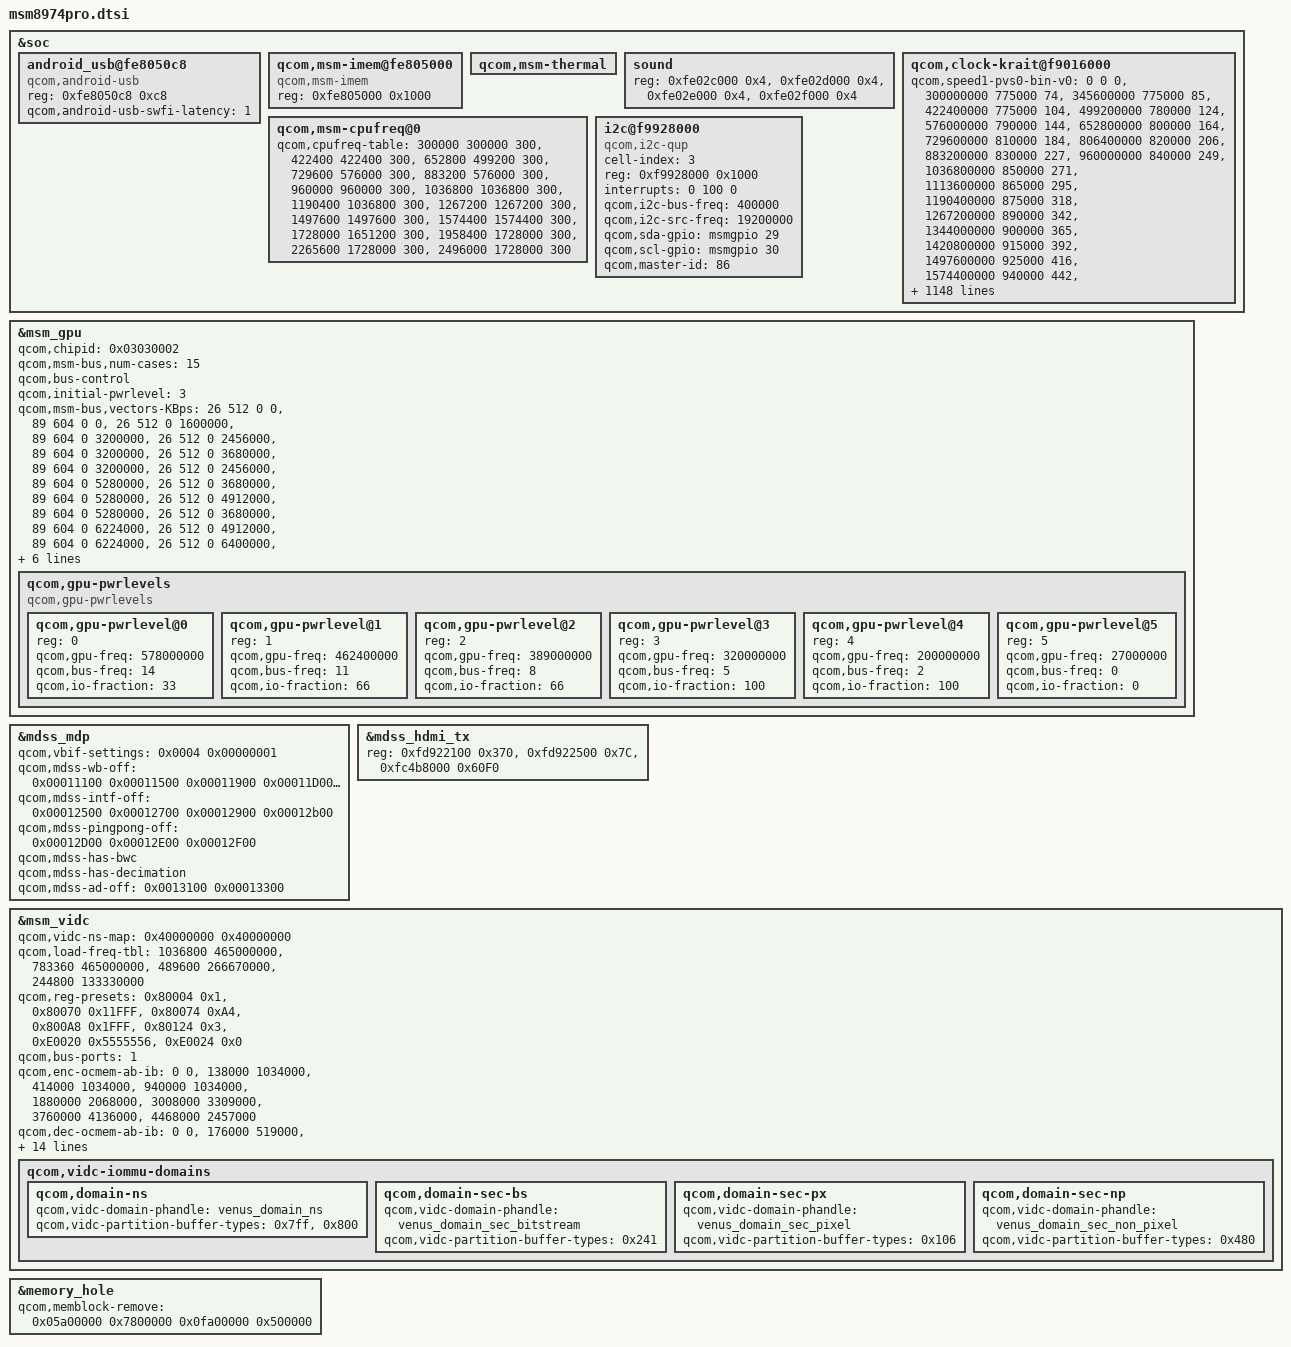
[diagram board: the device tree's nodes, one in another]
/* Copyright (c) 2013, The Linux Foundation. All rights reserved.
 *
 * This program is free software; you can redistribute it and/or modify
 * it under the terms of the GNU General Public License version 2 and
 * only version 2 as published by the Free Software Foundation.
 *
 * This program is distributed in the hope that it will be useful,
 * but WITHOUT ANY WARRANTY; without even the implied warranty of
 * MERCHANTABILITY or FITNESS FOR A PARTICULAR PURPOSE.  See the
 * GNU General Public License for more details.
 */

/*
 * As a general rule, only version-specific property overrides should be placed
 * inside this file. However, device definitions should be placed inside the
 * msm8974.dtsi file.
 */

/include/ "msm8974.dtsi"
/include/ "msm8974-v2-iommu.dtsi"
/include/ "msm8974-v2-iommu-domains.dtsi"
/include/ "msm8974pro-pm.dtsi"
/include/ "msm8974pro-ion.dtsi"

&soc {
	android_usb@fe8050c8 {
		compatible = "qcom,android-usb";
		reg = <0xfe8050c8 0xc8>;
		qcom,android-usb-swfi-latency = <1>;
	};

	qcom,msm-imem@fe805000 {
		compatible = "qcom,msm-imem";
		reg = <0xfe805000 0x1000>; /* Address and size of IMEM */
	};

	qcom,msm-thermal {
		/delete-property/ qcom,pmic-sw-mode-temp;
		/delete-property/ qcom,pmic-sw-mode-temp-hysteresis;
		/delete-property/ qcom,pmic-sw-mode-regs;
	};

	sound {
		reg = <0xfe02c000 0x4>,
		      <0xfe02d000 0x4>,
		      <0xfe02e000 0x4>,
		      <0xfe02f000 0x4>;
		reg-names = "lpaif_pri_mode_muxsel",
			    "lpaif_sec_mode_muxsel",
			    "lpaif_tert_mode_muxsel",
			    "lpaif_quat_mode_muxsel";
	};

	qcom,clock-krait@f9016000 {
		qcom,speed1-pvs0-bin-v0 =
			<          0       0    0 >,
			<  300000000  775000   74 >,
			<  345600000  775000   85 >,
			<  422400000  775000  104 >,
			<  499200000  780000  124 >,
			<  576000000  790000  144 >,
			<  652800000  800000  164 >,
			<  729600000  810000  184 >,
			<  806400000  820000  206 >,
			<  883200000  830000  227 >,
			<  960000000  840000  249 >,
			< 1036800000  850000  271 >,
			< 1113600000  865000  295 >,
			< 1190400000  875000  318 >,
			< 1267200000  890000  342 >,
			< 1344000000  900000  365 >,
			< 1420800000  915000  392 >,
			< 1497600000  925000  416 >,
			< 1574400000  940000  442 >,
			< 1651200000  955000  469 >,
			< 1728000000  970000  497 >,
			< 1804800000  985000  525 >,
			< 1881600000 1000000  554 >,
			< 1958400000 1015000  583 >,
			< 2035200000 1030000  613 >,
			< 2112000000 1045000  642 >,
			< 2150400000 1060000  663 >,
			< 2188800000 1060000  675 >,
			< 2265600000 1075000  708 >;

		qcom,speed1-pvs1-bin-v0 =
			<          0       0    0 >,
			<  300000000  775000   74 >,
			<  345600000  775000   85 >,
			<  422400000  775000  104 >,
			<  499200000  775000  124 >,
			<  576000000  775000  144 >,
			<  652800000  785000  164 >,
			<  729600000  795000  184 >,
			<  806400000  805000  206 >,
			<  883200000  815000  227 >,
			<  960000000  825000  249 >,
			< 1036800000  835000  271 >,
			< 1113600000  850000  295 >,
			< 1190400000  860000  318 >,
			< 1267200000  870000  342 >,
			< 1344000000  885000  365 >,
			< 1420800000  895000  392 >,
			< 1497600000  905000  416 >,
			< 1574400000  920000  442 >,
			< 1651200000  935000  469 >,
			< 1728000000  950000  497 >,
			< 1804800000  965000  525 >,
			< 1881600000  980000  554 >,
			< 1958400000  995000  583 >,
			< 2035200000 1005000  613 >,
			< 2112000000 1020000  642 >,
			< 2150400000 1035000  663 >,
			< 2188800000 1035000  675 >,
			< 2265600000 1050000  708 >;

		qcom,speed1-pvs2-bin-v0 =
			<          0       0    0 >,
			<  300000000  750000   74 >,
			<  345600000  750000   85 >,
			<  422400000  750000  104 >,
			<  499200000  750000  124 >,
			<  576000000  760000  144 >,
			<  652800000  770000  164 >,
			<  729600000  780000  184 >,
			<  806400000  790000  206 >,
			<  883200000  800000  227 >,
			<  960000000  810000  249 >,
			< 1036800000  820000  271 >,
			< 1113600000  830000  295 >,
			< 1190400000  840000  318 >,
			< 1267200000  850000  342 >,
			< 1344000000  865000  365 >,
			< 1420800000  875000  392 >,
			< 1497600000  885000  416 >,
			< 1574400000  900000  442 >,
			< 1651200000  915000  469 >,
			< 1728000000  930000  497 >,
			< 1804800000  945000  525 >,
			< 1881600000  955000  554 >,
			< 1958400000  970000  583 >,
			< 2035200000  980000  613 >,
			< 2112000000  995000  642 >,
			< 2150400000 1010000  663 >,
			< 2188800000 1010000  675 >,
			< 2265600000 1025000  708 >;

		qcom,speed1-pvs3-bin-v0 =
			<          0       0    0 >,
			<  300000000  750000   74 >,
			<  345600000  750000   85 >,
			<  422400000  750000  104 >,
			<  499200000  750000  124 >,
			<  576000000  750000  144 >,
			<  652800000  755000  164 >,
			<  729600000  765000  184 >,
			<  806400000  775000  206 >,
			<  883200000  785000  227 >,
			<  960000000  795000  249 >,
			< 1036800000  805000  271 >,
			< 1113600000  815000  295 >,
			< 1190400000  825000  318 >,
			< 1267200000  835000  342 >,
			< 1344000000  850000  365 >,
			< 1420800000  860000  392 >,
			< 1497600000  870000  416 >,
			< 1574400000  885000  442 >,
			< 1651200000  900000  469 >,
			< 1728000000  910000  497 >,
			< 1804800000  925000  525 >,
			< 1881600000  935000  554 >,
			< 1958400000  945000  583 >,
			< 2035200000  960000  613 >,
			< 2112000000  970000  642 >,
			< 2150400000  985000  663 >,
			< 2188800000  985000  675 >,
			< 2265600000 1000000  708 >;

		qcom,speed1-pvs4-bin-v0 =
			<          0       0    0 >,
			<  300000000  750000   74 >,
			<  345600000  750000   85 >,
			<  422400000  750000  104 >,
			<  499200000  750000  124 >,
			<  576000000  750000  144 >,
			<  652800000  750000  164 >,
			<  729600000  755000  184 >,
			<  806400000  765000  206 >,
			<  883200000  775000  227 >,
			<  960000000  785000  249 >,
			< 1036800000  795000  271 >,
			< 1113600000  805000  295 >,
			< 1190400000  815000  318 >,
			< 1267200000  825000  342 >,
			< 1344000000  835000  365 >,
			< 1420800000  845000  392 >,
			< 1497600000  855000  416 >,
			< 1574400000  870000  442 >,
			< 1651200000  885000  469 >,
			< 1728000000  895000  497 >,
			< 1804800000  905000  525 >,
			< 1881600000  915000  554 >,
			< 1958400000  925000  583 >,
			< 2035200000  935000  613 >,
			< 2112000000  950000  642 >,
			< 2150400000  960000  663 >,
			< 2188800000  960000  675 >,
			< 2265600000  975000  708 >;

		qcom,speed1-pvs5-bin-v0 =
			<          0       0    0 >,
			<  300000000  725000   74 >,
			<  345600000  725000   85 >,
			<  422400000  725000  104 >,
			<  499200000  725000  124 >,
			<  576000000  725000  144 >,
			<  652800000  735000  164 >,
			<  729600000  745000  184 >,
			<  806400000  755000  206 >,
			<  883200000  765000  227 >,
			<  960000000  775000  249 >,
			< 1036800000  785000  271 >,
			< 1113600000  795000  295 >,
			< 1190400000  805000  318 >,
			< 1267200000  815000  342 >,
			< 1344000000  825000  365 >,
			< 1420800000  835000  392 >,
			< 1497600000  845000  416 >,
			< 1574400000  855000  442 >,
			< 1651200000  865000  469 >,
			< 1728000000  875000  497 >,
			< 1804800000  885000  525 >,
			< 1881600000  895000  554 >,
			< 1958400000  905000  583 >,
			< 2035200000  915000  613 >,
			< 2112000000  930000  642 >,
			< 2150400000  940000  663 >,
			< 2188800000  940000  675 >,
			< 2265600000  950000  708 >;

		qcom,speed1-pvs6-bin-v0 =
			<          0       0    0 >,
			<  300000000  725000   74 >,
			<  345600000  725000   85 >,
			<  422400000  725000  104 >,
			<  499200000  725000  124 >,
			<  576000000  725000  144 >,
			<  652800000  725000  164 >,
			<  729600000  735000  184 >,
			<  806400000  745000  206 >,
			<  883200000  755000  227 >,
			<  960000000  765000  249 >,
			< 1036800000  775000  271 >,
			< 1113600000  785000  295 >,
			< 1190400000  795000  318 >,
			< 1267200000  805000  342 >,
			< 1344000000  815000  365 >,
			< 1420800000  825000  392 >,
			< 1497600000  835000  416 >,
			< 1574400000  845000  442 >,
			< 1651200000  850000  469 >,
			< 1728000000  860000  497 >,
			< 1804800000  870000  525 >,
			< 1881600000  880000  554 >,
			< 1958400000  890000  583 >,
			< 2035200000  895000  613 >,
			< 2112000000  905000  642 >,
			< 2150400000  915000  663 >,
			< 2188800000  915000  675 >,
			< 2265600000  925000  708 >;

		qcom,speed3-pvs0-bin-v0 =
			<          0       0    0 >,
			<  300000000  800000   76 >,
			<  345600000  800000   87 >,
			<  422400000  800000  106 >,
			<  499200000  800000  125 >,
			<  576000000  800000  145 >,
			<  652800000  810000  165 >,
			<  729600000  820000  186 >,
			<  806400000  830000  208 >,
			<  883200000  840000  229 >,
			<  960000000  850000  251 >,
			< 1036800000  860000  273 >,
			< 1113600000  870000  296 >,
			< 1190400000  880000  319 >,
			< 1267200000  890000  342 >,
			< 1344000000  900000  365 >,
			< 1420800000  910000  390 >,
			< 1497600000  920000  415 >,
			< 1574400000  930000  439 >,
			< 1651200000  945000  465 >,
			< 1728000000  960000  493 >,
			< 1804800000  975000  521 >,
			< 1881600000  990000  549 >,
			< 1958400000 1005000  579 >,
			< 2035200000 1020000  608 >,
			< 2112000000 1035000  638 >,
			< 2150400000 1050000  667 >,
			< 2188800000 1050000  667 >,
			< 2265600000 1065000  700 >,
			< 2342400000 1080000  734 >,
			< 2419200000 1095000  769 >,
			< 2457600000 1100000  785 >;

		qcom,speed3-pvs1-bin-v0 =
			<          0       0    0 >,
			<  300000000  800000   76 >,
			<  345600000  800000   87 >,
			<  422400000  800000  106 >,
			<  499200000  800000  125 >,
			<  576000000  800000  145 >,
			<  652800000  800000  165 >,
			<  729600000  800000  186 >,
			<  806400000  805000  208 >,
			<  883200000  815000  229 >,
			<  960000000  825000  251 >,
			< 1036800000  835000  273 >,
			< 1113600000  845000  296 >,
			< 1190400000  855000  319 >,
			< 1267200000  865000  342 >,
			< 1344000000  875000  365 >,
			< 1420800000  885000  390 >,
			< 1497600000  895000  415 >,
			< 1574400000  905000  439 >,
			< 1651200000  920000  465 >,
			< 1728000000  935000  493 >,
			< 1804800000  950000  521 >,
			< 1881600000  965000  549 >,
			< 1958400000  980000  579 >,
			< 2035200000  995000  608 >,
			< 2112000000 1010000  638 >,
			< 2150400000 1025000  667 >,
			< 2188800000 1025000  667 >,
			< 2265600000 1040000  700 >,
			< 2342400000 1055000  734 >,
			< 2419200000 1070000  769 >,
			< 2457600000 1075000  785 >;

		qcom,speed3-pvs2-bin-v0 =
			<          0       0    0 >,
			<  300000000  775000   76 >,
			<  345600000  775000   87 >,
			<  422400000  775000  106 >,
			<  499200000  775000  125 >,
			<  576000000  775000  145 >,
			<  652800000  775000  165 >,
			<  729600000  775000  186 >,
			<  806400000  780000  208 >,
			<  883200000  790000  229 >,
			<  960000000  800000  251 >,
			< 1036800000  810000  273 >,
			< 1113600000  820000  296 >,
			< 1190400000  830000  319 >,
			< 1267200000  840000  342 >,
			< 1344000000  850000  365 >,
			< 1420800000  860000  390 >,
			< 1497600000  870000  415 >,
			< 1574400000  880000  439 >,
			< 1651200000  895000  465 >,
			< 1728000000  910000  493 >,
			< 1804800000  925000  521 >,
			< 1881600000  940000  549 >,
			< 1958400000  955000  579 >,
			< 2035200000  970000  608 >,
			< 2112000000  985000  638 >,
			< 2150400000 1000000  667 >,
			< 2188800000 1000000  667 >,
			< 2265600000 1015000  700 >,
			< 2342400000 1030000  734 >,
			< 2419200000 1045000  769 >,
			< 2457600000 1050000  785 >;

		qcom,speed3-pvs3-bin-v0 =
			<          0       0    0 >,
			<  300000000  775000   76 >,
			<  345600000  775000   87 >,
			<  422400000  775000  106 >,
			<  499200000  775000  125 >,
			<  576000000  775000  145 >,
			<  652800000  775000  165 >,
			<  729600000  775000  186 >,
			<  806400000  775000  208 >,
			<  883200000  775000  229 >,
			<  960000000  780000  251 >,
			< 1036800000  785000  273 >,
			< 1113600000  795000  296 >,
			< 1190400000  805000  319 >,
			< 1267200000  815000  342 >,
			< 1344000000  825000  365 >,
			< 1420800000  835000  390 >,
			< 1497600000  845000  415 >,
			< 1574400000  855000  439 >,
			< 1651200000  870000  465 >,
			< 1728000000  885000  493 >,
			< 1804800000  900000  521 >,
			< 1881600000  915000  549 >,
			< 1958400000  930000  579 >,
			< 2035200000  945000  608 >,
			< 2112000000  960000  638 >,
			< 2150400000  975000  667 >,
			< 2188800000  975000  667 >,
			< 2265600000  990000  700 >,
			< 2342400000 1005000  734 >,
			< 2419200000 1020000  769 >,
			< 2457600000 1025000  785 >;

		qcom,speed3-pvs4-bin-v0 =
			<          0       0    0 >,
			<  300000000  775000   76 >,
			<  345600000  775000   87 >,
			<  422400000  775000  106 >,
			<  499200000  775000  125 >,
			<  576000000  775000  145 >,
			<  652800000  775000  165 >,
			<  729600000  775000  186 >,
			<  806400000  775000  208 >,
			<  883200000  775000  229 >,
			<  960000000  775000  251 >,
			< 1036800000  775000  273 >,
			< 1113600000  775000  296 >,
			< 1190400000  780000  319 >,
			< 1267200000  790000  342 >,
			< 1344000000  800000  365 >,
			< 1420800000  810000  390 >,
			< 1497600000  820000  415 >,
			< 1574400000  830000  439 >,
			< 1651200000  845000  465 >,
			< 1728000000  860000  493 >,
			< 1804800000  875000  521 >,
			< 1881600000  890000  549 >,
			< 1958400000  905000  579 >,
			< 2035200000  920000  608 >,
			< 2112000000  935000  638 >,
			< 2150400000  950000  667 >,
			< 2188800000  950000  667 >,
			< 2265600000  965000  700 >,
			< 2342400000  980000  734 >,
			< 2419200000  995000  769 >,
			< 2457600000 1000000  785 >;

		qcom,speed3-pvs5-bin-v0 =
			<          0       0    0 >,
			<  300000000  750000   76 >,
			<  345600000  750000   87 >,
			<  422400000  750000  106 >,
			<  499200000  750000  125 >,
			<  576000000  750000  145 >,
			<  652800000  750000  165 >,
			<  729600000  750000  186 >,
			<  806400000  750000  208 >,
			<  883200000  750000  229 >,
			<  960000000  750000  251 >,
			< 1036800000  750000  273 >,
			< 1113600000  750000  296 >,
			< 1190400000  760000  319 >,
			< 1267200000  770000  342 >,
			< 1344000000  780000  365 >,
			< 1420800000  790000  390 >,
			< 1497600000  800000  415 >,
			< 1574400000  810000  439 >,
			< 1651200000  820000  465 >,
			< 1728000000  835000  493 >,
			< 1804800000  850000  521 >,
			< 1881600000  865000  549 >,
			< 1958400000  880000  579 >,
			< 2035200000  895000  608 >,
			< 2112000000  910000  638 >,
			< 2150400000  925000  667 >,
			< 2188800000  925000  667 >,
			< 2265600000  940000  700 >,
			< 2342400000  955000  734 >,
			< 2419200000  970000  769 >,
			< 2457600000  975000  785 >;

		qcom,speed3-pvs6-bin-v0 =
			<          0       0    0 >,
			<  300000000  750000   76 >,
			<  345600000  750000   87 >,
			<  422400000  750000  106 >,
			<  499200000  750000  125 >,
			<  576000000  750000  145 >,
			<  652800000  750000  165 >,
			<  729600000  750000  186 >,
			<  806400000  750000  208 >,
			<  883200000  750000  229 >,
			<  960000000  750000  251 >,
			< 1036800000  750000  273 >,
			< 1113600000  750000  296 >,
			< 1190400000  750000  319 >,
			< 1267200000  755000  342 >,
			< 1344000000  765000  365 >,
			< 1420800000  775000  390 >,
			< 1497600000  785000  415 >,
			< 1574400000  795000  439 >,
			< 1651200000  805000  465 >,
			< 1728000000  815000  493 >,
			< 1804800000  825000  521 >,
			< 1881600000  840000  549 >,
			< 1958400000  855000  579 >,
			< 2035200000  870000  608 >,
			< 2112000000  885000  638 >,
			< 2150400000  900000  667 >,
			< 2188800000  900000  667 >,
			< 2265600000  915000  700 >,
			< 2342400000  930000  734 >,
			< 2419200000  945000  769 >,
			< 2457600000  950000  785 >;

		qcom,speed1-pvs0-bin-v1 =
			<          0       0    0 >,
			<  300000000  800000   76 >,
			<  345600000  810000   87 >,
			<  422400000  820000  108 >,
			<  499200000  830000  129 >,
			<  576000000  840000  150 >,
			<  652800000  850000  171 >,
			<  729600000  860000  193 >,
			<  806400000  870000  215 >,
			<  883200000  880000  237 >,
			<  960000000  890000  260 >,
			< 1036800000  900000  282 >,
			< 1113600000  910000  306 >,
			< 1190400000  920000  330 >,
			< 1267200000  930000  354 >,
			< 1344000000  940000  378 >,
			< 1420800000  955000  404 >,
			< 1497600000  970000  431 >,
			< 1574400000  985000  458 >,
			< 1651200000 1000000  486 >,
			< 1728000000 1015000  515 >,
			< 1804800000 1030000  543 >,
			< 1881600000 1045000  572 >,
			< 1958400000 1060000  604 >,
			< 2035200000 1075000  636 >,
			< 2112000000 1090000  669 >,
			< 2150400000 1105000  703 >,
			< 2188800000 1105000  703 >,
			< 2265600000 1120000  738 >;

		qcom,speed1-pvs1-bin-v1 =
			<          0       0    0 >,
			<  300000000  800000   76 >,
			<  345600000  800000   87 >,
			<  422400000  810000  108 >,
			<  499200000  820000  129 >,
			<  576000000  830000  150 >,
			<  652800000  840000  171 >,
			<  729600000  850000  193 >,
			<  806400000  860000  215 >,
			<  883200000  870000  237 >,
			<  960000000  880000  260 >,
			< 1036800000  890000  282 >,
			< 1113600000  900000  306 >,
			< 1190400000  910000  330 >,
			< 1267200000  920000  354 >,
			< 1344000000  930000  378 >,
			< 1420800000  945000  404 >,
			< 1497600000  960000  431 >,
			< 1574400000  975000  458 >,
			< 1651200000  990000  486 >,
			< 1728000000 1005000  515 >,
			< 1804800000 1020000  543 >,
			< 1881600000 1035000  572 >,
			< 1958400000 1050000  604 >,
			< 2035200000 1065000  636 >,
			< 2112000000 1080000  669 >,
			< 2150400000 1095000  703 >,
			< 2188800000 1095000  703 >,
			< 2265600000 1110000  738 >;

		qcom,speed1-pvs2-bin-v1 =
			<          0       0    0 >,
			<  300000000  800000   76 >,
			<  345600000  800000   87 >,
			<  422400000  800000  108 >,
			<  499200000  810000  129 >,
			<  576000000  820000  150 >,
			<  652800000  830000  171 >,
			<  729600000  840000  193 >,
			<  806400000  850000  215 >,
			<  883200000  860000  237 >,
			<  960000000  870000  260 >,
			< 1036800000  880000  282 >,
			< 1113600000  890000  306 >,
			< 1190400000  900000  330 >,
			< 1267200000  910000  354 >,
			< 1344000000  920000  378 >,
			< 1420800000  935000  404 >,
			< 1497600000  950000  431 >,
			< 1574400000  965000  458 >,
			< 1651200000  980000  486 >,
			< 1728000000  995000  515 >,
			< 1804800000 1010000  543 >,
			< 1881600000 1025000  572 >,
			< 1958400000 1040000  604 >,
			< 2035200000 1055000  636 >,
			< 2112000000 1070000  669 >,
			< 2150400000 1085000  703 >,
			< 2188800000 1085000  703 >,
			< 2265600000 1100000  738 >;

		qcom,speed1-pvs3-bin-v1 =
			<          0       0    0 >,
			<  300000000  800000   76 >,
			<  345600000  800000   87 >,
			<  422400000  800000  108 >,
			<  499200000  800000  129 >,
			<  576000000  810000  150 >,
			<  652800000  820000  171 >,
			<  729600000  830000  193 >,
			<  806400000  840000  215 >,
			<  883200000  850000  237 >,
			<  960000000  860000  260 >,
			< 1036800000  870000  282 >,
			< 1113600000  880000  306 >,
			< 1190400000  890000  330 >,
			< 1267200000  900000  354 >,
			< 1344000000  910000  378 >,
			< 1420800000  925000  404 >,
			< 1497600000  940000  431 >,
			< 1574400000  955000  458 >,
			< 1651200000  970000  486 >,
			< 1728000000  985000  515 >,
			< 1804800000 1000000  543 >,
			< 1881600000 1015000  572 >,
			< 1958400000 1030000  604 >,
			< 2035200000 1045000  636 >,
			< 2112000000 1060000  669 >,
			< 2150400000 1075000  703 >,
			< 2188800000 1075000  703 >,
			< 2265600000 1090000  738 >;

		qcom,speed1-pvs4-bin-v1 =
			<          0       0    0 >,
			<  300000000  800000   76 >,
			<  345600000  800000   87 >,
			<  422400000  800000  108 >,
			<  499200000  800000  129 >,
			<  576000000  800000  150 >,
			<  652800000  810000  171 >,
			<  729600000  820000  193 >,
			<  806400000  830000  215 >,
			<  883200000  840000  237 >,
			<  960000000  850000  260 >,
			< 1036800000  860000  282 >,
			< 1113600000  870000  306 >,
			< 1190400000  880000  330 >,
			< 1267200000  890000  354 >,
			< 1344000000  900000  378 >,
			< 1420800000  915000  404 >,
			< 1497600000  930000  431 >,
			< 1574400000  945000  458 >,
			< 1651200000  960000  486 >,
			< 1728000000  975000  515 >,
			< 1804800000  990000  543 >,
			< 1881600000 1005000  572 >,
			< 1958400000 1020000  604 >,
			< 2035200000 1035000  636 >,
			< 2112000000 1050000  669 >,
			< 2150400000 1065000  703 >,
			< 2188800000 1065000  703 >,
			< 2265600000 1080000  738 >;

		qcom,speed1-pvs5-bin-v1 =
			<          0       0    0 >,
			<  300000000  800000   76 >,
			<  345600000  800000   87 >,
			<  422400000  800000  108 >,
			<  499200000  800000  129 >,
			<  576000000  800000  150 >,
			<  652800000  800000  171 >,
			<  729600000  810000  193 >,
			<  806400000  820000  215 >,
			<  883200000  830000  237 >,
			<  960000000  840000  260 >,
			< 1036800000  850000  282 >,
			< 1113600000  860000  306 >,
			< 1190400000  870000  330 >,
			< 1267200000  880000  354 >,
			< 1344000000  890000  378 >,
			< 1420800000  905000  404 >,
			< 1497600000  920000  431 >,
			< 1574400000  935000  458 >,
			< 1651200000  950000  486 >,
			< 1728000000  965000  515 >,
			< 1804800000  980000  543 >,
			< 1881600000  995000  572 >,
			< 1958400000 1010000  604 >,
			< 2035200000 1025000  636 >,
			< 2112000000 1040000  669 >,
			< 2150400000 1055000  703 >,
			< 2188800000 1055000  703 >,
			< 2265600000 1070000  738 >;

		qcom,speed1-pvs6-bin-v1 =
			<          0       0    0 >,
			<  300000000  775000   76 >,
			<  345600000  775000   87 >,
			<  422400000  775000  108 >,
			<  499200000  775000  129 >,
			<  576000000  780000  150 >,
			<  652800000  790000  171 >,
			<  729600000  800000  193 >,
			<  806400000  810000  215 >,
			<  883200000  820000  237 >,
			<  960000000  830000  260 >,
			< 1036800000  840000  282 >,
			< 1113600000  850000  306 >,
			< 1190400000  860000  330 >,
			< 1267200000  870000  354 >,
			< 1344000000  880000  378 >,
			< 1420800000  895000  404 >,
			< 1497600000  910000  431 >,
			< 1574400000  925000  458 >,
			< 1651200000  940000  486 >,
			< 1728000000  955000  515 >,
			< 1804800000  970000  543 >,
			< 1881600000  985000  572 >,
			< 1958400000 1000000  604 >,
			< 2035200000 1015000  636 >,
			< 2112000000 1030000  669 >,
			< 2150400000 1045000  703 >,
			< 2188800000 1045000  703 >,
			< 2265600000 1060000  738 >;

		qcom,speed1-pvs7-bin-v1 =
			<          0       0    0 >,
			<  300000000  775000   76 >,
			<  345600000  775000   87 >,
			<  422400000  775000  108 >,
			<  499200000  775000  129 >,
			<  576000000  775000  150 >,
			<  652800000  780000  171 >,
			<  729600000  790000  193 >,
			<  806400000  800000  215 >,
			<  883200000  810000  237 >,
			<  960000000  820000  260 >,
			< 1036800000  830000  282 >,
			< 1113600000  840000  306 >,
			< 1190400000  850000  330 >,
			< 1267200000  860000  354 >,
			< 1344000000  870000  378 >,
			< 1420800000  885000  404 >,
			< 1497600000  900000  431 >,
			< 1574400000  915000  458 >,
			< 1651200000  930000  486 >,
			< 1728000000  945000  515 >,
			< 1804800000  960000  543 >,
			< 1881600000  975000  572 >,
			< 1958400000  990000  604 >,
			< 2035200000 1005000  636 >,
			< 2112000000 1020000  669 >,
			< 2150400000 1035000  703 >,
			< 2188800000 1035000  703 >,
			< 2265600000 1050000  738 >;

		qcom,speed1-pvs8-bin-v1 =
			<          0       0    0 >,
			<  300000000  775000   76 >,
			<  345600000  775000   87 >,
			<  422400000  775000  108 >,
			<  499200000  775000  129 >,
			<  576000000  775000  150 >,
			<  652800000  775000  171 >,
			<  729600000  780000  193 >,
			<  806400000  790000  215 >,
			<  883200000  800000  237 >,
			<  960000000  810000  260 >,
			< 1036800000  820000  282 >,
			< 1113600000  830000  306 >,
			< 1190400000  840000  330 >,
			< 1267200000  850000  354 >,
			< 1344000000  860000  378 >,
			< 1420800000  875000  404 >,
			< 1497600000  890000  431 >,
			< 1574400000  905000  458 >,
			< 1651200000  920000  486 >,
			< 1728000000  935000  515 >,
			< 1804800000  950000  543 >,
			< 1881600000  965000  572 >,
			< 1958400000  980000  604 >,
			< 2035200000  995000  636 >,
			< 2112000000 1010000  669 >,
			< 2150400000 1025000  703 >,
			< 2188800000 1025000  703 >,
			< 2265600000 1040000  738 >;

		qcom,speed1-pvs9-bin-v1 =
			<          0       0    0 >,
			<  300000000  775000   76 >,
			<  345600000  775000   87 >,
			<  422400000  775000  108 >,
			<  499200000  775000  129 >,
			<  576000000  775000  150 >,
			<  652800000  775000  171 >,
			<  729600000  775000  193 >,
			<  806400000  780000  215 >,
			<  883200000  790000  237 >,
			<  960000000  800000  260 >,
			< 1036800000  810000  282 >,
			< 1113600000  820000  306 >,
			< 1190400000  830000  330 >,
			< 1267200000  840000  354 >,
			< 1344000000  850000  378 >,
			< 1420800000  865000  404 >,
			< 1497600000  880000  431 >,
			< 1574400000  895000  458 >,
			< 1651200000  910000  486 >,
			< 1728000000  925000  515 >,
			< 1804800000  940000  543 >,
			< 1881600000  955000  572 >,
			< 1958400000  970000  604 >,
			< 2035200000  985000  636 >,
			< 2112000000 1000000  669 >,
			< 2150400000 1015000  703 >,
			< 2188800000 1015000  703 >,
			< 2265600000 1030000  738 >;

		qcom,speed1-pvs10-bin-v1 =
			<          0       0    0 >,
			<  300000000  775000   76 >,
			<  345600000  775000   87 >,
			<  422400000  775000  108 >,
			<  499200000  775000  129 >,
			<  576000000  775000  150 >,
			<  652800000  775000  171 >,
			<  729600000  775000  193 >,
			<  806400000  775000  215 >,
			<  883200000  780000  237 >,
			<  960000000  790000  260 >,
			< 1036800000  800000  282 >,
			< 1113600000  810000  306 >,
			< 1190400000  820000  330 >,
			< 1267200000  830000  354 >,
			< 1344000000  840000  378 >,
			< 1420800000  855000  404 >,
			< 1497600000  870000  431 >,
			< 1574400000  885000  458 >,
			< 1651200000  900000  486 >,
			< 1728000000  915000  515 >,
			< 1804800000  930000  543 >,
			< 1881600000  945000  572 >,
			< 1958400000  960000  604 >,
			< 2035200000  975000  636 >,
			< 2112000000  990000  669 >,
			< 2150400000 1005000  703 >,
			< 2188800000 1005000  703 >,
			< 2265600000 1020000  738 >;

		qcom,speed1-pvs11-bin-v1 =
			<          0       0    0 >,
			<  300000000  775000   76 >,
			<  345600000  775000   87 >,
			<  422400000  775000  108 >,
			<  499200000  775000  129 >,
			<  576000000  775000  150 >,
			<  652800000  775000  171 >,
			<  729600000  775000  193 >,
			<  806400000  775000  215 >,
			<  883200000  775000  237 >,
			<  960000000  780000  260 >,
			< 1036800000  790000  282 >,
			< 1113600000  800000  306 >,
			< 1190400000  810000  330 >,
			< 1267200000  820000  354 >,
			< 1344000000  830000  378 >,
			< 1420800000  845000  404 >,
			< 1497600000  860000  431 >,
			< 1574400000  875000  458 >,
			< 1651200000  890000  486 >,
			< 1728000000  905000  515 >,
			< 1804800000  920000  543 >,
			< 1881600000  935000  572 >,
			< 1958400000  950000  604 >,
			< 2035200000  965000  636 >,
			< 2112000000  980000  669 >,
			< 2150400000  995000  703 >,
			< 2188800000  995000  703 >,
			< 2265600000 1010000  738 >;

		qcom,speed1-pvs12-bin-v1 =
			<          0       0    0 >,
			<  300000000  775000   76 >,
			<  345600000  775000   87 >,
			<  422400000  775000  108 >,
			<  499200000  775000  129 >,
			<  576000000  775000  150 >,
			<  652800000  775000  171 >,
			<  729600000  775000  193 >,
			<  806400000  775000  215 >,
			<  883200000  775000  237 >,
			<  960000000  775000  260 >,
			< 1036800000  780000  282 >,
			< 1113600000  790000  306 >,
			< 1190400000  800000  330 >,
			< 1267200000  810000  354 >,
			< 1344000000  820000  378 >,
			< 1420800000  835000  404 >,
			< 1497600000  850000  431 >,
			< 1574400000  865000  458 >,
			< 1651200000  880000  486 >,
			< 1728000000  895000  515 >,
			< 1804800000  910000  543 >,
			< 1881600000  925000  572 >,
			< 1958400000  940000  604 >,
			< 2035200000  955000  636 >,
			< 2112000000  970000  669 >,
			< 2150400000  985000  703 >,
			< 2188800000  985000  703 >,
			< 2265600000 1000000  738 >;

		qcom,speed1-pvs13-bin-v1 =
			<          0       0    0 >,
			<  300000000  775000   76 >,
			<  345600000  775000   87 >,
			<  422400000  775000  108 >,
			<  499200000  775000  129 >,
			<  576000000  775000  150 >,
			<  652800000  775000  171 >,
			<  729600000  775000  193 >,
			<  806400000  775000  215 >,
			<  883200000  775000  237 >,
			<  960000000  775000  260 >,
			< 1036800000  775000  282 >,
			< 1113600000  780000  306 >,
			< 1190400000  790000  330 >,
			< 1267200000  800000  354 >,
			< 1344000000  810000  378 >,
			< 1420800000  825000  404 >,
			< 1497600000  840000  431 >,
			< 1574400000  855000  458 >,
			< 1651200000  870000  486 >,
			< 1728000000  885000  515 >,
			< 1804800000  900000  543 >,
			< 1881600000  915000  572 >,
			< 1958400000  930000  604 >,
			< 2035200000  945000  636 >,
			< 2112000000  960000  669 >,
			< 2150400000  975000  703 >,
			< 2188800000  975000  703 >,
			< 2265600000  990000  738 >;

		qcom,speed1-pvs14-bin-v1 =
			<          0       0    0 >,
			<  300000000  750000   76 >,
			<  345600000  750000   87 >,
			<  422400000  750000  108 >,
			<  499200000  750000  129 >,
			<  576000000  750000  150 >,
			<  652800000  750000  171 >,
			<  729600000  750000  193 >,
			<  806400000  750000  215 >,
			<  883200000  750000  237 >,
			<  960000000  750000  260 >,
			< 1036800000  760000  282 >,
			< 1113600000  770000  306 >,
			< 1190400000  780000  330 >,
			< 1267200000  790000  354 >,
			< 1344000000  800000  378 >,
			< 1420800000  815000  404 >,
			< 1497600000  830000  431 >,
			< 1574400000  845000  458 >,
			< 1651200000  860000  486 >,
			< 1728000000  875000  515 >,
			< 1804800000  890000  543 >,
			< 1881600000  905000  572 >,
			< 1958400000  920000  604 >,
			< 2035200000  935000  636 >,
			< 2112000000  950000  669 >,
			< 2150400000  965000  703 >,
			< 2188800000  965000  703 >,
			< 2265600000  980000  738 >;

		qcom,speed1-pvs15-bin-v1 =
			<          0       0    0 >,
			<  300000000  750000   76 >,
			<  345600000  750000   87 >,
			<  422400000  750000  108 >,
			<  499200000  750000  129 >,
			<  576000000  750000  150 >,
			<  652800000  750000  171 >,
			<  729600000  750000  193 >,
			<  806400000  750000  215 >,
			<  883200000  750000  237 >,
			<  960000000  750000  260 >,
			< 1036800000  750000  282 >,
			< 1113600000  760000  306 >,
			< 1190400000  770000  330 >,
			< 1267200000  780000  354 >,
			< 1344000000  790000  378 >,
			< 1420800000  805000  404 >,
			< 1497600000  820000  431 >,
			< 1574400000  835000  458 >,
			< 1651200000  850000  486 >,
			< 1728000000  865000  515 >,
			< 1804800000  880000  543 >,
			< 1881600000  895000  572 >,
			< 1958400000  910000  604 >,
			< 2035200000  925000  636 >,
			< 2112000000  940000  669 >,
			< 2150400000  955000  703 >,
			< 2188800000  955000  703 >,
			< 2265600000  970000  738 >;

		qcom,speed3-pvs0-bin-v1 =
			<          0       0    0 >,
			<  300000000  800000   76 >,
			<  345600000  800000   87 >,
			<  422400000  800000  106 >,
			<  499200000  810000  126 >,
			<  576000000  820000  147 >,
			<  652800000  830000  168 >,
			<  729600000  840000  189 >,
			<  806400000  850000  211 >,
			<  883200000  860000  233 >,
			<  960000000  870000  256 >,
			< 1036800000  880000  278 >,
			< 1113600000  890000  301 >,
			< 1190400000  900000  324 >,
			< 1267200000  910000  348 >,
			< 1344000000  920000  372 >,
			< 1420800000  930000  396 >,
			< 1497600000  940000  421 >,
			< 1574400000  950000  446 >,
			< 1651200000  965000  473 >,
			< 1728000000  980000  501 >,
			< 1804800000  995000  529 >,
			< 1881600000 1010000  558 >,
			< 1958400000 1025000  588 >,
			< 2035200000 1040000  617 >,
			< 2112000000 1055000  649 >,
			< 2150400000 1070000  682 >,
			< 2188800000 1070000  682 >,
			< 2265600000 1085000  716 >,
			< 2342400000 1100000  751 >,
			< 2419200000 1115000  786 >,
			< 2457600000 1120000  802 >;

		qcom,speed3-pvs1-bin-v1 =
			<          0       0    0 >,
			<  300000000  800000   76 >,
			<  345600000  800000   87 >,
			<  422400000  800000  106 >,
			<  499200000  800000  126 >,
			<  576000000  810000  147 >,
			<  652800000  820000  168 >,
			<  729600000  830000  189 >,
			<  806400000  840000  211 >,
			<  883200000  850000  233 >,
			<  960000000  860000  256 >,
			< 1036800000  870000  278 >,
			< 1113600000  880000  301 >,
			< 1190400000  890000  324 >,
			< 1267200000  900000  348 >,
			< 1344000000  910000  372 >,
			< 1420800000  920000  396 >,
			< 1497600000  930000  421 >,
			< 1574400000  940000  446 >,
			< 1651200000  955000  473 >,
			< 1728000000  970000  501 >,
			< 1804800000  985000  529 >,
			< 1881600000 1000000  558 >,
			< 1958400000 1015000  588 >,
			< 2035200000 1030000  617 >,
			< 2112000000 1045000  649 >,
			< 2150400000 1060000  682 >,
			< 2188800000 1060000  682 >,
			< 2265600000 1075000  716 >,
			< 2342400000 1090000  751 >,
			< 2419200000 1105000  786 >,
			< 2457600000 1110000  802 >;

		qcom,speed3-pvs2-bin-v1 =
			<          0       0    0 >,
			<  300000000  800000   76 >,
			<  345600000  800000   87 >,
			<  422400000  800000  106 >,
			<  499200000  800000  126 >,
			<  576000000  800000  147 >,
			<  652800000  810000  168 >,
			<  729600000  820000  189 >,
			<  806400000  830000  211 >,
			<  883200000  840000  233 >,
			<  960000000  850000  256 >,
			< 1036800000  860000  278 >,
			< 1113600000  870000  301 >,
			< 1190400000  880000  324 >,
			< 1267200000  890000  348 >,
			< 1344000000  900000  372 >,
			< 1420800000  910000  396 >,
			< 1497600000  920000  421 >,
			< 1574400000  930000  446 >,
			< 1651200000  945000  473 >,
			< 1728000000  960000  501 >,
			< 1804800000  975000  529 >,
			< 1881600000  990000  558 >,
			< 1958400000 1005000  588 >,
			< 2035200000 1020000  617 >,
			< 2112000000 1035000  649 >,
			< 2150400000 1050000  682 >,
			< 2188800000 1050000  682 >,
			< 2265600000 1065000  716 >,
			< 2342400000 1080000  751 >,
			< 2419200000 1095000  786 >,
			< 2457600000 1100000  802 >;

		qcom,speed3-pvs3-bin-v1 =
			<          0       0    0 >,
			<  300000000  800000   76 >,
			<  345600000  800000   87 >,
			<  422400000  800000  106 >,
			<  499200000  800000  126 >,
			<  576000000  800000  147 >,
			<  652800000  800000  168 >,
			<  729600000  810000  189 >,
			<  806400000  820000  211 >,
			<  883200000  830000  233 >,
			<  960000000  840000  256 >,
			< 1036800000  850000  278 >,
			< 1113600000  860000  301 >,
			< 1190400000  870000  324 >,
			< 1267200000  880000  348 >,
			< 1344000000  890000  372 >,
			< 1420800000  900000  396 >,
			< 1497600000  910000  421 >,
			< 1574400000  920000  446 >,
			< 1651200000  935000  473 >,
			< 1728000000  950000  501 >,
			< 1804800000  965000  529 >,
			< 1881600000  980000  558 >,
			< 1958400000  995000  588 >,
			< 2035200000 1010000  617 >,
			< 2112000000 1025000  649 >,
			< 2150400000 1040000  682 >,
			< 2188800000 1040000  682 >,
			< 2265600000 1055000  716 >,
			< 2342400000 1070000  751 >,
			< 2419200000 1085000  786 >,
			< 2457600000 1090000  802 >;

		qcom,speed3-pvs4-bin-v1 =
			<          0       0    0 >,
			<  300000000  800000   76 >,
			<  345600000  800000   87 >,
			<  422400000  800000  106 >,
			<  499200000  800000  126 >,
			<  576000000  800000  147 >,
			<  652800000  800000  168 >,
			<  729600000  800000  189 >,
			<  806400000  810000  211 >,
			<  883200000  820000  233 >,
			<  960000000  830000  256 >,
			< 1036800000  840000  278 >,
			< 1113600000  850000  301 >,
			< 1190400000  860000  324 >,
			< 1267200000  870000  348 >,
			< 1344000000  880000  372 >,
			< 1420800000  890000  396 >,
			< 1497600000  900000  421 >,
			< 1574400000  910000  446 >,
			< 1651200000  925000  473 >,
			< 1728000000  940000  501 >,
			< 1804800000  955000  529 >,
			< 1881600000  970000  558 >,
			< 1958400000  985000  588 >,
			< 2035200000 1000000  617 >,
			< 2112000000 1015000  649 >,
			< 2150400000 1030000  682 >,
			< 2188800000 1030000  682 >,
			< 2265600000 1045000  716 >,
			< 2342400000 1060000  751 >,
			< 2419200000 1075000  786 >,
			< 2457600000 1080000  802 >;

		qcom,speed3-pvs5-bin-v1 =
			<          0       0    0 >,
			<  300000000  800000   76 >,
			<  345600000  800000   87 >,
			<  422400000  800000  106 >,
			<  499200000  800000  126 >,
			<  576000000  800000  147 >,
			<  652800000  800000  168 >,
			<  729600000  800000  189 >,
			<  806400000  800000  211 >,
			<  883200000  810000  233 >,
			<  960000000  820000  256 >,
			< 1036800000  830000  278 >,
			< 1113600000  840000  301 >,
			< 1190400000  850000  324 >,
			< 1267200000  860000  348 >,
			< 1344000000  870000  372 >,
			< 1420800000  880000  396 >,
			< 1497600000  890000  421 >,
			< 1574400000  900000  446 >,
			< 1651200000  915000  473 >,
			< 1728000000  930000  501 >,
			< 1804800000  945000  529 >,
			< 1881600000  960000  558 >,
			< 1958400000  975000  588 >,
			< 2035200000  990000  617 >,
			< 2112000000 1005000  649 >,
			< 2150400000 1020000  682 >,
			< 2188800000 1020000  682 >,
			< 2265600000 1035000  716 >,
			< 2342400000 1050000  751 >,
			< 2419200000 1065000  786 >,
			< 2457600000 1070000  802 >;

		qcom,speed3-pvs6-bin-v1 =
			<          0       0    0 >,
			<  300000000  775000   76 >,
			<  345600000  775000   87 >,
			<  422400000  775000  106 >,
			<  499200000  775000  126 >,
			<  576000000  775000  147 >,
			<  652800000  775000  168 >,
			<  729600000  780000  189 >,
			<  806400000  790000  211 >,
			<  883200000  800000  233 >,
			<  960000000  810000  256 >,
			< 1036800000  820000  278 >,
			< 1113600000  830000  301 >,
			< 1190400000  840000  324 >,
			< 1267200000  850000  348 >,
			< 1344000000  860000  372 >,
			< 1420800000  870000  396 >,
			< 1497600000  880000  421 >,
			< 1574400000  890000  446 >,
			< 1651200000  905000  473 >,
			< 1728000000  920000  501 >,
			< 1804800000  935000  529 >,
			< 1881600000  950000  558 >,
			< 1958400000  965000  588 >,
			< 2035200000  980000  617 >,
			< 2112000000  995000  649 >,
			< 2150400000 1010000  682 >,
			< 2188800000 1010000  682 >,
			< 2265600000 1025000  716 >,
			< 2342400000 1040000  751 >,
			< 2419200000 1055000  786 >,
			< 2457600000 1060000  802 >;

		qcom,speed3-pvs7-bin-v1 =
			<          0       0    0 >,
			<  300000000  775000   76 >,
			<  345600000  775000   87 >,
			<  422400000  775000  106 >,
			<  499200000  775000  126 >,
			<  576000000  775000  147 >,
			<  652800000  775000  168 >,
			<  729600000  775000  189 >,
			<  806400000  780000  211 >,
			<  883200000  790000  233 >,
			<  960000000  800000  256 >,
			< 1036800000  810000  278 >,
			< 1113600000  820000  301 >,
			< 1190400000  830000  324 >,
			< 1267200000  840000  348 >,
			< 1344000000  850000  372 >,
			< 1420800000  860000  396 >,
			< 1497600000  870000  421 >,
			< 1574400000  880000  446 >,
			< 1651200000  895000  473 >,
			< 1728000000  910000  501 >,
			< 1804800000  925000  529 >,
			< 1881600000  940000  558 >,
			< 1958400000  955000  588 >,
			< 2035200000  970000  617 >,
			< 2112000000  985000  649 >,
			< 2150400000 1000000  682 >,
			< 2188800000 1000000  682 >,
			< 2265600000 1015000  716 >,
			< 2342400000 1030000  751 >,
			< 2419200000 1045000  786 >,
			< 2457600000 1050000  802 >;

		qcom,speed3-pvs8-bin-v1 =
			<          0       0    0 >,
			<  300000000  775000   76 >,
			<  345600000  775000   87 >,
			<  422400000  775000  106 >,
			<  499200000  775000  126 >,
			<  576000000  775000  147 >,
			<  652800000  775000  168 >,
			<  729600000  775000  189 >,
			<  806400000  775000  211 >,
			<  883200000  780000  233 >,
			<  960000000  790000  256 >,
			< 1036800000  800000  278 >,
			< 1113600000  810000  301 >,
			< 1190400000  820000  324 >,
			< 1267200000  830000  348 >,
			< 1344000000  840000  372 >,
			< 1420800000  850000  396 >,
			< 1497600000  860000  421 >,
			< 1574400000  870000  446 >,
			< 1651200000  885000  473 >,
			< 1728000000  900000  501 >,
			< 1804800000  915000  529 >,
			< 1881600000  930000  558 >,
			< 1958400000  945000  588 >,
			< 2035200000  960000  617 >,
			< 2112000000  975000  649 >,
			< 2150400000  990000  682 >,
			< 2188800000  990000  682 >,
			< 2265600000 1005000  716 >,
			< 2342400000 1020000  751 >,
			< 2419200000 1035000  786 >,
			< 2457600000 1040000  802 >;

		qcom,speed3-pvs9-bin-v1 =
			<          0       0    0 >,
			<  300000000  775000   76 >,
			<  345600000  775000   87 >,
			<  422400000  775000  106 >,
			<  499200000  775000  126 >,
			<  576000000  775000  147 >,
			<  652800000  775000  168 >,
			<  729600000  775000  189 >,
			<  806400000  775000  211 >,
			<  883200000  775000  233 >,
			<  960000000  780000  256 >,
			< 1036800000  790000  278 >,
			< 1113600000  800000  301 >,
			< 1190400000  810000  324 >,
			< 1267200000  820000  348 >,
			< 1344000000  830000  372 >,
			< 1420800000  840000  396 >,
			< 1497600000  850000  421 >,
			< 1574400000  860000  446 >,
			< 1651200000  875000  473 >,
			< 1728000000  890000  501 >,
			< 1804800000  905000  529 >,
			< 1881600000  920000  558 >,
			< 1958400000  935000  588 >,
			< 2035200000  950000  617 >,
			< 2112000000  965000  649 >,
			< 2150400000  980000  682 >,
			< 2188800000  980000  682 >,
			< 2265600000  995000  716 >,
			< 2342400000 1010000  751 >,
			< 2419200000 1025000  786 >,
			< 2457600000 1030000  802 >;

		qcom,speed3-pvs10-bin-v1 =
			<          0       0    0 >,
			<  300000000  775000   76 >,
			<  345600000  775000   87 >,
			<  422400000  775000  106 >,
			<  499200000  775000  126 >,
			<  576000000  775000  147 >,
			<  652800000  775000  168 >,
			<  729600000  775000  189 >,
			<  806400000  775000  211 >,
			<  883200000  775000  233 >,
			<  960000000  775000  256 >,
			< 1036800000  780000  278 >,
			< 1113600000  790000  301 >,
			< 1190400000  800000  324 >,
			< 1267200000  810000  348 >,
			< 1344000000  820000  372 >,
			< 1420800000  830000  396 >,
			< 1497600000  840000  421 >,
			< 1574400000  850000  446 >,
			< 1651200000  865000  473 >,
			< 1728000000  880000  501 >,
			< 1804800000  895000  529 >,
			< 1881600000  910000  558 >,
			< 1958400000  925000  588 >,
			< 2035200000  940000  617 >,
			< 2112000000  955000  649 >,
			< 2150400000  970000  682 >,
			< 2188800000  970000  682 >,
			< 2265600000  985000  716 >,
			< 2342400000 1000000  751 >,
			< 2419200000 1015000  786 >,
			< 2457600000 1020000  802 >;

		qcom,speed3-pvs11-bin-v1 =
			<          0       0    0 >,
			<  300000000  775000   76 >,
			<  345600000  775000   87 >,
			<  422400000  775000  106 >,
			<  499200000  775000  126 >,
			<  576000000  775000  147 >,
			<  652800000  775000  168 >,
			<  729600000  775000  189 >,
			<  806400000  775000  211 >,
			<  883200000  775000  233 >,
			<  960000000  775000  256 >,
			< 1036800000  775000  278 >,
			< 1113600000  780000  301 >,
			< 1190400000  790000  324 >,
			< 1267200000  800000  348 >,
			< 1344000000  810000  372 >,
			< 1420800000  820000  396 >,
			< 1497600000  830000  421 >,
			< 1574400000  840000  446 >,
			< 1651200000  855000  473 >,
			< 1728000000  870000  501 >,
			< 1804800000  885000  529 >,
			< 1881600000  900000  558 >,
			< 1958400000  915000  588 >,
			< 2035200000  930000  617 >,
			< 2112000000  945000  649 >,
			< 2150400000  960000  682 >,
			< 2188800000  960000  682 >,
			< 2265600000  975000  716 >,
			< 2342400000  990000  751 >,
			< 2419200000 1005000  786 >,
			< 2457600000 1010000  802 >;

		qcom,speed3-pvs12-bin-v1 =
			<          0       0    0 >,
			<  300000000  775000   76 >,
			<  345600000  775000   87 >,
			<  422400000  775000  106 >,
			<  499200000  775000  126 >,
			<  576000000  775000  147 >,
			<  652800000  775000  168 >,
			<  729600000  775000  189 >,
			<  806400000  775000  211 >,
			<  883200000  775000  233 >,
			<  960000000  775000  256 >,
			< 1036800000  775000  278 >,
			< 1113600000  775000  301 >,
			< 1190400000  780000  324 >,
			< 1267200000  790000  348 >,
			< 1344000000  800000  372 >,
			< 1420800000  810000  396 >,
			< 1497600000  820000  421 >,
			< 1574400000  830000  446 >,
			< 1651200000  845000  473 >,
			< 1728000000  860000  501 >,
			< 1804800000  875000  529 >,
			< 1881600000  890000  558 >,
			< 1958400000  905000  588 >,
			< 2035200000  920000  617 >,
			< 2112000000  935000  649 >,
			< 2150400000  950000  682 >,
			< 2188800000  950000  682 >,
			< 2265600000  965000  716 >,
			< 2342400000  980000  751 >,
			< 2419200000  995000  786 >,
			< 2457600000 1000000  802 >;

		qcom,speed3-pvs13-bin-v1 =
			<          0       0    0 >,
			<  300000000  775000   76 >,
			<  345600000  775000   87 >,
			<  422400000  775000  106 >,
			<  499200000  775000  126 >,
			<  576000000  775000  147 >,
			<  652800000  775000  168 >,
			<  729600000  775000  189 >,
			<  806400000  775000  211 >,
			<  883200000  775000  233 >,
			<  960000000  775000  256 >,
			< 1036800000  775000  278 >,
			< 1113600000  775000  301 >,
			< 1190400000  775000  324 >,
			< 1267200000  780000  348 >,
			< 1344000000  790000  372 >,
			< 1420800000  800000  396 >,
			< 1497600000  810000  421 >,
			< 1574400000  820000  446 >,
			< 1651200000  835000  473 >,
			< 1728000000  850000  501 >,
			< 1804800000  865000  529 >,
			< 1881600000  880000  558 >,
			< 1958400000  895000  588 >,
			< 2035200000  910000  617 >,
			< 2112000000  925000  649 >,
			< 2150400000  940000  682 >,
			< 2188800000  940000  682 >,
			< 2265600000  955000  716 >,
			< 2342400000  970000  751 >,
			< 2419200000  985000  786 >,
			< 2457600000  990000  802 >;

		qcom,speed3-pvs14-bin-v1 =
			<          0       0    0 >,
			<  300000000  750000   76 >,
			<  345600000  750000   87 >,
			<  422400000  750000  106 >,
			<  499200000  750000  126 >,
			<  576000000  750000  147 >,
			<  652800000  750000  168 >,
			<  729600000  750000  189 >,
			<  806400000  750000  211 >,
			<  883200000  750000  233 >,
			<  960000000  750000  256 >,
			< 1036800000  750000  278 >,
			< 1113600000  750000  301 >,
			< 1190400000  760000  324 >,
			< 1267200000  770000  348 >,
			< 1344000000  780000  372 >,
			< 1420800000  790000  396 >,
			< 1497600000  800000  421 >,
			< 1574400000  810000  446 >,
			< 1651200000  825000  473 >,
			< 1728000000  840000  501 >,
			< 1804800000  855000  529 >,
			< 1881600000  870000  558 >,
			< 1958400000  885000  588 >,
			< 2035200000  900000  617 >,
			< 2112000000  915000  649 >,
			< 2150400000  930000  682 >,
			< 2188800000  930000  682 >,
			< 2265600000  945000  716 >,
			< 2342400000  960000  751 >,
			< 2419200000  975000  786 >,
			< 2457600000  980000  802 >;

		qcom,speed3-pvs15-bin-v1 =
			<          0       0    0 >,
			<  300000000  750000   76 >,
			<  345600000  750000   87 >,
			<  422400000  750000  106 >,
			<  499200000  750000  126 >,
			<  576000000  750000  147 >,
			<  652800000  750000  168 >,
			<  729600000  750000  189 >,
			<  806400000  750000  211 >,
			<  883200000  750000  233 >,
			<  960000000  750000  256 >,
			< 1036800000  750000  278 >,
			< 1113600000  750000  301 >,
			< 1190400000  750000  324 >,
			< 1267200000  760000  348 >,
			< 1344000000  770000  372 >,
			< 1420800000  780000  396 >,
			< 1497600000  790000  421 >,
			< 1574400000  800000  446 >,
			< 1651200000  815000  473 >,
			< 1728000000  830000  501 >,
			< 1804800000  845000  529 >,
			< 1881600000  860000  558 >,
			< 1958400000  875000  588 >,
			< 2035200000  890000  617 >,
			< 2112000000  905000  649 >,
			< 2150400000  920000  682 >,
			< 2188800000  920000  682 >,
			< 2265600000  935000  716 >,
			< 2342400000  950000  751 >,
			< 2419200000  965000  786 >,
			< 2457600000  970000  802 >;
	};

	qcom,msm-cpufreq@0 {
		qcom,cpufreq-table =
			<  300000  300000 300 /* 37.5 MHz */ >,
			<  422400  422400 300 /* 37.5 MHz */ >,
			<  652800  499200 300 /* 37.5 MHz */ >,
			<  729600  576000 300 /* 37.5 MHz */ >,
			<  883200  576000 300 /* 37.5 MHz */ >,
			<  960000  960000 300 /* 37.5 MHz */ >,
			< 1036800 1036800 300 /* 37.5 MHz */ >,
			< 1190400 1036800 300 /* 37.5 MHz */ >,
			< 1267200 1267200 300 /* 37.5 MHz */ >,
			< 1497600 1497600 300 /* 37.5 MHz */ >,
			< 1574400 1574400 300 /* 37.5 MHz */ >,
			< 1728000 1651200 300 /* 37.5 MHz */ >,
			< 1958400 1728000 300 /* 37.5 MHz */ >,
			< 2265600 1728000 300 /* 37.5 MHz */ >,
			< 2496000 1728000 300 /* 37.5 MHz */ >;
	};

	i2c@f9928000 { /* BLSP-1 QUP-6 */
		cell-index = <3>;
		compatible = "qcom,i2c-qup";
		reg = <0xf9928000 0x1000>;
		#address-cells = <1>;
		#size-cells = <0>;
		reg-names = "qup_phys_addr";
		interrupts = <0 100 0>;
		interrupt-names = "qup_err_intr";
		qcom,i2c-bus-freq = <400000>;
		qcom,i2c-src-freq = <19200000>;
		qcom,sda-gpio = <&msmgpio 29 0>;
		qcom,scl-gpio = <&msmgpio 30 0>;
		qcom,master-id = <86>;
	};
};

/* GPU overrides */
&msm_gpu {
	/* Updated chip ID */
	qcom,chipid = <0x03030002>;
	qcom,msm-bus,num-cases = <15>;
	qcom,bus-control;
	qcom,initial-pwrlevel = <3>;

	/* Updated bus bandwidth requirements */
	qcom,msm-bus,vectors-KBps =
		/* Off */
		<26 512 0 0>, <89 604 0 0>,
		/* Sub-SVS / SVS */
		<26 512 0 1600000>, <89 604 0 3200000>,
		/* SVS */
		<26 512 0 2456000>, <89 604 0 3200000>,
		/* low Nominal / SVS */
		<26 512 0 3680000>, <89 604 0 3200000>,
		/* SVS / low Nominal */
		<26 512 0 2456000>, <89 604 0 5280000>,
		/* low Nominal / low Nominal */
		<26 512 0 3680000>, <89 604 0 5280000>,
		/* Nominal / low Nominal */
		<26 512 0 4912000>, <89 604 0 5280000>,
		/* low Nominal / Nominal */
		<26 512 0 3680000>, <89 604 0 6224000>,
		/* Nominal / Nominal */
		<26 512 0 4912000>, <89 604 0 6224000>,
		/* low Turbo / Nominal */
		<26 512 0 6400000>, <89 604 0 6224000>,
		/* Nominal / low Turbo */
		<26 512 0 4912000>, <89 604 0 7398000>,
		/* low Turbo / low Turbo */
		<26 512 0 6400000>, <89 604 0 7398000>,
		/* Turbo / low Turbo */
		<26 512 0 7464000>, <89 604 0 7398000>,
		/* Nominal / Turbo */
		<26 512 0 4912000>, <89 604 0 9248000>,
		/* Turbo / Turbo */
		<26 512 0 7464000>, <89 604 0 9248000>;

       qcom,gpu-pwrlevels {
               #address-cells = <1>;
               #size-cells = <0>;

               compatible = "qcom,gpu-pwrlevels";

               qcom,gpu-pwrlevel@0 {
                       reg = <0>;
                       qcom,gpu-freq = <578000000>;
                       qcom,bus-freq = <14>;
                       qcom,io-fraction = <33>;
               };

               qcom,gpu-pwrlevel@1 {
                       reg = <1>;
                       qcom,gpu-freq = <462400000>;
                       qcom,bus-freq = <11>;
                       qcom,io-fraction = <66>;
               };

               qcom,gpu-pwrlevel@2 {
                       reg = <2>;
                       qcom,gpu-freq = <389000000>;
                       qcom,bus-freq = <8>;
                       qcom,io-fraction = <66>;
               };

               qcom,gpu-pwrlevel@3 {
                       reg = <3>;
                       qcom,gpu-freq = <320000000>;
                       qcom,bus-freq = <5>;
                       qcom,io-fraction = <100>;
               };

               qcom,gpu-pwrlevel@4 {
                       reg = <4>;
                       qcom,gpu-freq = <200000000>;
                       qcom,bus-freq = <2>;
                       qcom,io-fraction = <100>;
               };

               qcom,gpu-pwrlevel@5 {
                       reg = <5>;
                       qcom,gpu-freq = <27000000>;
                       qcom,bus-freq = <0>;
                       qcom,io-fraction = <0>;
               };
       };
};

&mdss_mdp {
	qcom,vbif-settings = <0x0004 0x00000001>;

	qcom,mdss-wb-off = <0x00011100 0x00011500
			    0x00011900 0x00011D00 0x00012100>;
	qcom,mdss-intf-off = <0x00012500 0x00012700
			      0x00012900 0x00012b00>;
	qcom,mdss-pingpong-off = <0x00012D00 0x00012E00 0x00012F00>;
	qcom,mdss-has-bwc;
	qcom,mdss-has-decimation;
	qcom,mdss-ad-off = <0x0013100 0x00013300>;
};

&mdss_hdmi_tx {
	reg =	<0xfd922100 0x370>,
		<0xfd922500 0x7C>,
		<0xfc4b8000 0x60F0>;
	reg-names = "core_physical", "phy_physical", "qfprom_physical";
};

&msm_vidc {
	qcom,vidc-ns-map = <0x40000000 0x40000000>;
	qcom,load-freq-tbl = <1036800 465000000>,
		<783360 465000000>,
		<489600 266670000>,
		<244800 133330000>;
	qcom,reg-presets = <0x80004 0x1>,
		<0x80070 0x11FFF>,
		<0x80074 0xA4>,
		<0x800A8 0x1FFF>,
		<0x80124 0x3>,
		<0xE0020 0x5555556>,
		<0xE0024 0x0>;
	qcom,bus-ports = <1>;
	qcom,enc-ocmem-ab-ib = <0 0>,
		<138000 1034000>,
		<414000 1034000>,
		<940000 1034000>,
		<1880000 2068000>,
		<3008000 3309000>,
		<3760000 4136000>,
		<4468000 2457000>;
	qcom,dec-ocmem-ab-ib = <0 0>,
		<176000 519000>,
		<456000 519000>,
		<864000 519000>,
		<1728000 1038000>,
		<2766000 1661000>,
		<3456000 2076000>,
		<3662000 2198000>;
	qcom,enc-ddr-ab-ib = <0 0>,
		<120000 302000>,
		<364000 302000>,
		<804000 302000>,
		<1608000 604000>,
		<2576000 967000>,
		<4680000 1404000>,
		<4988000 1496000>;
	qcom,dec-ddr-ab-ib = <0 0>,
		<208000 303000>,
		<536000 1600000>,
		<1012000 1600000>,
		<2024000 1600000>,
		<3240000 1600000>,
		<4048000 1600000>,
		<4264000 1600000>;
	qcom,max-hw-load = <1281600>; /* max(4k X 2304 @ 24, 4k X 2160 @ 30) + 1080p @ 30 */
	qcom,buffer-type-tz-usage-table = <0x241 0x1>,
					<0x106 0x2>,
					<0x480 0x3>;
	qcom,vidc-iommu-domains {
		qcom,domain-ns {
			qcom,vidc-domain-phandle = <&venus_domain_ns>;
			qcom,vidc-partition-buffer-types = <0x7ff>,
							<0x800>;
		};
		qcom,domain-sec-bs {
			qcom,vidc-domain-phandle = <&venus_domain_sec_bitstream>;
			qcom,vidc-partition-buffer-types = <0x241>;
		};
		qcom,domain-sec-px {
			qcom,vidc-domain-phandle = <&venus_domain_sec_pixel>;
			qcom,vidc-partition-buffer-types = <0x106>;
		};
		qcom,domain-sec-np {
			qcom,vidc-domain-phandle = <&venus_domain_sec_non_pixel>;
			qcom,vidc-partition-buffer-types = <0x480>;
		};
	};
};

&memory_hole {
	qcom,memblock-remove = <0x05a00000 0x7800000
				0x0fa00000 0x500000>; /* Address and size of the hole */
};
